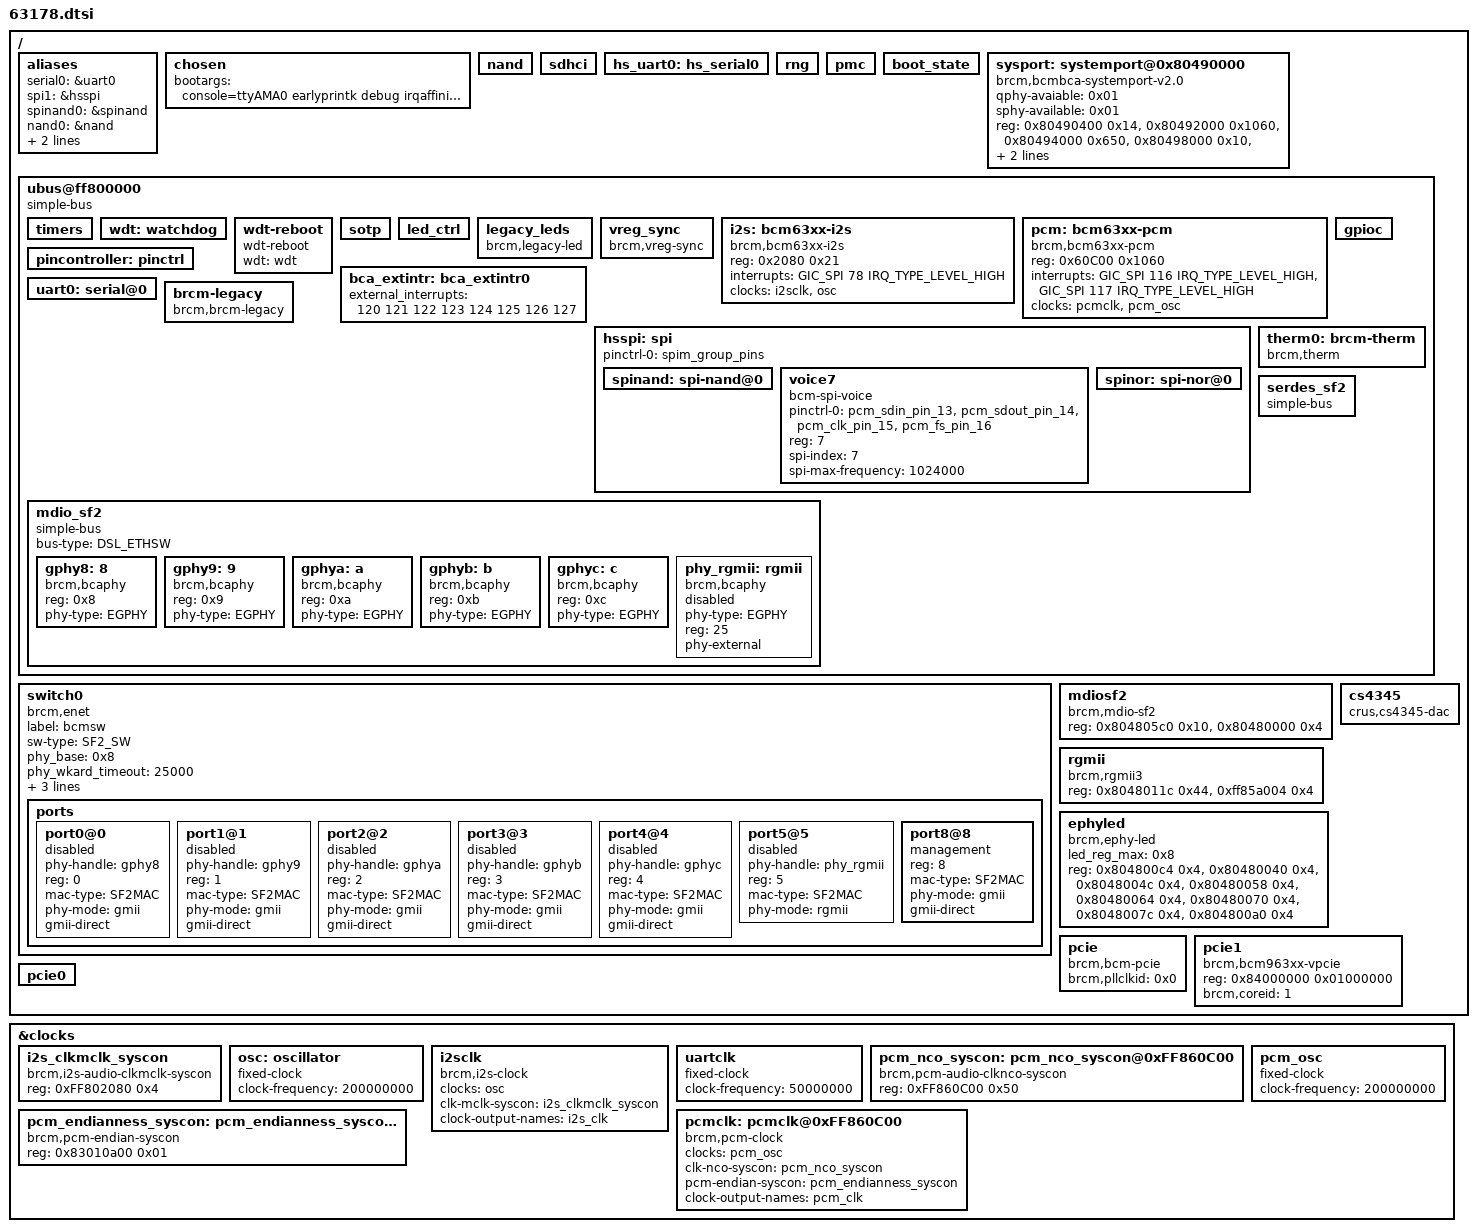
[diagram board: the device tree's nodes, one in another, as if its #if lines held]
/dts-v1/;

#define PMU_CORE0_SPI                   7
#define PMU_CORE1_SPI                   8
#define PMU_CORE2_SPI                   9


#include "linux_autoconf.h"

/* bootstrap reserved memory */
#include "../boot_rsvdmem.dtsi"

/ {
        /* arch */
	#define MODEL "Broadcom BCM963178"
	#define COMPATIBLE "brcm,bcm963178"
	#include "../ip/bcm_cortexA7_tri.dtsi"

	#define PERIPH_CLK		200000000
	#define HS_SPI_PLL_CLK	200000000
	#include "../ip/bcm_clocks.dtsi"

	/* broadcom memory reservations */
	#include "../bcm_rsvdmem.dtsi"

	aliases {
		serial0 = &uart0;
		spi1 = &hsspi; /* 0 = legacy, 1 = high speed */
		spinand0 = &spinand;
		nand0 = &nand;
		spinor0 = &spinor;
		hs_serial0  = &hs_uart0;
	};
	chosen {
		bootargs = "console=ttyAMA0 earlyprintk debug irqaffinity=0 pci=pcie_bus_safe isolcpus=2 rootwait";
        };

	/* memc */
	#define BP_DDR_SUPPORT_VTT                  1
	#define BP_DDR_SUPPORT_VTT_DIS_PASVTERM     0
	#define BP_DDR_63178_DEFAULT           BP_DDR_VTT_DIS_NOTERM
	#include "../ip/memc.dtsi"

	nand: nand {
		#define NAND_CTRL_OFFSET		0xff801800
		#define NAND_CTRL_SIZE			0x400
		#define NAND_INTR_OFFSET		0xff802000
		#define NAND_INTR_SIZE			0x10
		#define NAND_CACHE_OFFSET		0xff801C00
		#define NAND_CACHE_SIZE			0x200
		#include "../ip/bcm_nand7_1.dtsi"
	};
        /* EMMC */
	sdhci: sdhci {
		#define SDHCI_OFFSET			0xff810000
		#define SDHCI_SIZE			0x100
		#define SDHCI_TOPCFG_OFFSET		0xff810100
		#define SDHCI_TOPCFG_SIZE		0x100
		#define SDHCI_BOOT_OFFSET		0xff810200
		#define SDHCI_BOOT_SIZE			0x40
		#define SDHCI_AHBSS_CTRL_OFFSET		0xff810300
		#define SDHCI_AHBSS_CTRL_SIZE		0x100
		#define SDIO_EMMC_SPI			86
		#include "../ip/bcm_sdhci.dtsi"
	};
	hs_uart0: hs_serial0 {
		#define UART_OFFSET			0xff810400
		#define UART_SIZE			0x1E0
		#define UART_SPI			34
		#include "../ip/bcm_hs_uart.dtsi"
	};
	/* RNG */
	rng: rng {
		#define RNG200_OFFSET                   0xff800b80
		#define RNG200_SIZE                     0x30
		#include "../ip/bcm_rng200.dtsi"
	};

	/* PMC */
	pmc: pmc {
		#define PMC_REG_OFFSET              0x80301018 
		#define PMC_REG_SIZE                0x5080
		#define PROCMON_REG_OFFSET          0x80320000
		#define PROCMON_REG_SIZE            0x240
		#define MAESTRO_REG_OFFSET          0x80300400
		#define MAESTRO_REG_SIZE            0x5d0
		#define MAESTRO_DTCM_REG_OFFSET     0x80380000
		#define MAESTRO_DTCM_REG_SIZE       0x1000
		#include "../ip/bcm_pmc_3_2.dtsi"
	};

	/* boot state */
	boot_state: boot_state {
		#define RESET_REASON_OFFSET  0xff802628
		#define RESET_REASON_SIZE    0x4
		#define RESET_STATUS_OFFSET  0xff85a03c
		#define RESET_STATUS_SIZE    0x4
		#include "../ip/bcm_boot_state_v2.dtsi"
	};


	sysport: systemport@0x80490000 {
		compatible = "brcm,bcmbca-systemport-v2.0";
		qphy-avaiable=<0x01>;
		sphy-available=<0x01>;
		reg-names = "systemport-rbuf-base", "systemport-rdma-base",
				"systemport-tdma-base",
				"systemport-gib-base",
				"systemport-umac-base",
				"systemport-topctrl-base";
		reg =		<0x80490400 0x14>,
				<0x80492000 0x1060>,
				<0x80494000 0x650>,
				<0x80498000 0x10>,
				<0x00000000 0x00>,  
				<0x80490000 0x10>;
		ethsw = <&switch0>;
	};


	ubus@ff800000 {
		compatible = "simple-bus";
		#address-cells = <1>;
		#size-cells = <1>;
		ranges = <0 0xff800000 0x7fffff>;

		/* periph timers */
		timers: timers {
			#define TIMERS_OFFSET		0x400
			#define TIMERS__SIZE		0x48
			#define TIMER0_SPI			11
			#define TIMER1_SPI			12
			#define TIMER2_SPI			13
			#define TIMER3_SPI			14
			#include "../ip/bcm_timer.dtsi"
		};

		/* watchdog */
		wdt: watchdog {
			#define WATCHDOG_OFFSET			0x480
			#define WATCHDOG_SIZE			0x10
			#define WATCHDOG_TIMEOUT		80
			#include "../ip/bcm_wdt.dtsi"
		};
		/* watchdog reboot */
		wdt-reboot {
			compatible = "wdt-reboot";
			wdt = <&wdt>;
		};

		/* sotp */
		sotp {
			#define SOTP_OFFSET			0xc00
			#define SOTP_SIZE			0x84
			#include "../ip/bcm_sotp.dtsi"
		};
		
		/* Led Controller */
		led_ctrl: led_ctrl {
			#define CLED_GLBL_CTRL_OFFSET           0x3000
			#define CLED_GLBL_CTRL_SIZE             0x4
			#define CLED_HW_EN_OFFSET               0x3004
			#define CLED_HW_EN_SIZE                 0x4
			#define CLED_SER_SHIFT_OFFSET           0x3008
			#define CLED_SER_SHIFT_SIZE             0x4
			#define CLED_HW_POLARITY_OFFSET         0x300c
			#define CLED_HW_POLARITY_SIZE           0x4
			#define CLED_SW_SET_OFFSET              0x3010
			#define CLED_SW_SET_SIZE                0x4
			#define CLED_SW_POLARITY_OFFSET         0x3014
			#define CLED_SW_POLARITY_SIZE           0x4
			#define CLED_CH_ACTIVATE_OFFSET         0x301c
			#define CLED_CH_ACTIVATE_SIZE           0x4
			#define CLED_XX_CONFIG_OFFSET           0x3020
			#define CLED_XX_CONFIG_SIZE             0x200
			#define CLED_SERIAL_POLARITY_OFFSET     0x3454
			#define CLED_SERIAL_POLARITY_SIZE       0x4
			#define CLED_PARALLEL_POLARITY_OFFSET   0x3018
			#define CLED_PARALLEL_POLARITY_SIZE     0x4
			#define MAX_SUPPORTED_LEDS              32

			status = "okay";
			#include "../ip/bcm_cled_legacy_ctrl.dtsi"
			#include "63178_leds.dtsi"
		};

		legacy_leds: legacy_leds {
			compatible = "brcm,legacy-led";
		};

		vreg_sync: vreg_sync {
			compatible = "brcm,vreg-sync";
		};

		i2s: bcm63xx-i2s {
			compatible = "brcm,bcm63xx-i2s";
			reg = <0x2080 0x21>;
			interrupts = <GIC_SPI 78 IRQ_TYPE_LEVEL_HIGH>;
			clocks = <&i2sclk>, <&osc>;
			clock-names = "i2sclk","i2sosc"; 
		};
		pcm: bcm63xx-pcm {
			compatible = "brcm,bcm63xx-pcm";
			reg = <0x60C00 0x1060>;
			interrupts = <GIC_SPI 116 IRQ_TYPE_LEVEL_HIGH>,<GIC_SPI 117 IRQ_TYPE_LEVEL_HIGH>;
			clocks = <&pcmclk>, <&pcm_osc>;
			clock-names = "pcmclk","pcmosc"; 
		};
		/* pinctrl */
		pincontroller: pinctrl {
			#define PINCTRL_OFFSET       0x554
			#define PINCTRL_SIZE         0xc
			#define PINCTRL_NUM_PINS     88
			#define PINCTRL_NUM_FUNC     8
			#define PINCTRL_GPIO_FUNC    5
			#include "../ip/bcm_bca_pinctrl.dtsi"
			#include "63178_pinctrl.dtsi"
		};
		/* gpio */
		gpioc: gpioc {
			#define GPIO_DIR_OFFSET      0x500
			#define GPIO_DIR_SIZE        0x20
			#define GPIO_DATA_OFFSET     0x520
			#define GPIO_DATA_SIZE       0x20
			#define NUM_OF_GPIOS         88
			#include "../ip/bcm_bca_gpio.dtsi"
		};

		/* external interrups */
		bca_extintr: bca_extintr0 {
			#define EXTINTR_OFFSET       0x4
			#define EXTINTR_SIZE         0x48
			#define MAX_EXT_INTR         8
			#include "../ip/bcm_bca_extintr.dtsi"
			external_interrupts = <120 121 122 123 124 125 126 127>;
		};
		
		/* UART 1*/
		uart0: serial@0 {
			#define UART_OFFSET			0x12000
			#define UART_SIZE			0x1000
			#define UART_SPI			32
			#define UART_CLK_LABEL			refclk50mhz
			#define UART_CLK			50000000
			#include "../ip/bcm_arm_uart.dtsi"
		};
		/* HS SPI */
		hsspi: spi {
			pinctrl-0 = <&spim_group_pins>;
			pinctrl-names = "default";
			#define HS_SPI_OFFSET			0x1000
			#define HS_SPI_SIZE			0x600
			#define HS_SPI_MAX_FREQ			100000000
			#define HS_SPIM_SPI			37
			#include "../ip/bcm_hsspi.dtsi"
			spinand: spi-nand@0 {
				#define SPINAND_MAX_FREQ	100000000
				#include "../ip/bcm_spinand.dtsi"
			};
			voice7 {
				pinctrl-0 = <&pcm_sdin_pin_13 &pcm_sdout_pin_14 &pcm_clk_pin_15 &pcm_fs_pin_16>;
				pinctrl-names = "default";
				compatible = "bcm-spi-voice";
				reg = <7>; /* chip select 7 */
				spi-index = <7>;/* ZSI/ISI header position index */
				spi-max-frequency = <1024000>;
			};	
			spinor: spi-nor@0 {
				#define SPINOR_MAX_FREQ	50000000
				#include "../ip/bcm_spinor.dtsi"
			};
		};
		brcm-legacy {
			compatible = "brcm,brcm-legacy";
		};
		


		therm0: brcm-therm {
			compatible = "brcm,therm";
			status = "okay";
		};

		mdio_sf2: mdio_sf2 {
			compatible = "simple-bus";
			bus-type = "DSL_ETHSW";

			gphy8:8 {
				compatible = "brcm,bcaphy";
				reg = <0x8>;
				phy-type = "EGPHY";
			};
			gphy9:9 {
				compatible = "brcm,bcaphy";
				reg = <0x9>;
				phy-type = "EGPHY";
			};
			gphya:a {
				compatible = "brcm,bcaphy";
				reg = <0xa>;
				phy-type = "EGPHY";
			};
			gphyb:b {
				compatible = "brcm,bcaphy";
				reg = <0xb>;
				phy-type = "EGPHY";
			};
			gphyc:c {
				compatible = "brcm,bcaphy";
				reg = <0xc>;
				phy-type = "EGPHY";
			};
			phy_rgmii:rgmii {
				compatible = "brcm,bcaphy";
				phy-type = "EGPHY";
				reg = <25>;
				status = "disabled";
				phy-external;
			};
		};

		serdes_sf2: serdes_sf2 {
			compatible = "simple-bus";
		};
	};

	switch0:switch0 {
		compatible = "brcm,enet", "brcm,bcmbca-sf2";
		label = "bcmsw";
		sw-type = "SF2_SW";

		phy_base = <0x8>;
		phy_wkard_timeout = <25000>;
		reg-names = "switchcore-base",
					"switchreg-base",
					"switchmdio-base",
					"qphy-ctrl",
					"sphy-ctrl",
					"phy-test-ctrl";

		reg = <0x80400000 0x72724>,
			<0x80480000 0x458>,
			<0x804805c0 0x10>,
			<0x8048001c 0x04>,
			<0x80480024 0x04>,
			<0x80480018 0x04>;

		ports {
			port0@0 {
				phy-handle = <&gphy8>;
				reg = <0>;
				mac-type = "SF2MAC";
				phy-mode = "gmii";
				gmii-direct;
				status = "disabled";
			};
			port1@1 {
				phy-handle = <&gphy9>;
				reg = <1>;
				mac-type = "SF2MAC";
				phy-mode = "gmii";
				gmii-direct;
				status = "disabled";
			};
			port2@2 {
				phy-handle = <&gphya>;
				reg = <2>;
				mac-type = "SF2MAC";
				phy-mode = "gmii";
				gmii-direct;
				status = "disabled";
			};
			port3@3 {
				phy-handle = <&gphyb>;
				reg = <3>;
				mac-type = "SF2MAC";
				phy-mode = "gmii";
				gmii-direct;
				status = "disabled";
			};
			port4@4 {
				phy-handle = <&gphyc>;
				reg = <4>;
				mac-type = "SF2MAC";
				phy-mode = "gmii";
				gmii-direct;
				status = "disabled";
			};
			port5@5 {
				phy-handle = <&phy_rgmii>;
				reg = <5>;
				mac-type = "SF2MAC";
				phy-mode = "rgmii";
				status = "disabled";
			};
			port8@8 {
				management;
				reg = <8>;
				mac-type = "SF2MAC";
				phy-mode = "gmii";
				gmii-direct;
				status = "okay";
			};
		};
	};

	mdiosf2 {
		compatible = "brcm,mdio-sf2";
		reg = <0x804805c0 0x10>,
		      <0x80480000 0x4>;
	};

	rgmii: rgmii {
		compatible = "brcm,rgmii3";
		reg = <0x8048011c  0x44>,
		      <0xff85a004  0x4>;
	};

	ephyled {
	    compatible = "brcm,ephy-led";
            led_reg_max=<0x8>;
            reg-names = "aggregate_ctrl", "led_reg_0", "led_reg_1", "led_reg_2", "led_reg_3", "led_reg_4", "led_reg_5", "led_reg_8"; 
            reg = <0x804800c4 0x4>, < 0x80480040 0x4>, < 0x8048004c 0x4>, < 0x80480058 0x4>, < 0x80480064 0x4>, < 0x80480070 0x4>, < 0x8048007c 0x4>, < 0x804800a0 0x4>;
	};


	cs4345 {
		compatible = "crus,cs4345-dac";
	};

#if defined(CONFIG_BCM_PCIE_HCD) || defined(CONFIG_BCM_PCIE_HCD_MODULE)
	/* pcie common */
	pcie: pcie {
		compatible = "brcm,bcm-pcie";
		device_type = "cpci";
		brcm,pllclkid = <0x0>;
	};

	/* pcie core 1 (internal wifi first) */
	pcie1: pcie1 {
		compatible = "brcm,bcm963xx-vpcie";
		device_type = "vpci";
		reg = <0x84000000 0x01000000>;

		brcm,coreid = <1>;
	};

	/* pcie core 0 */
	pcie0: pcie0 {
		#define PCIE_ID				0
		#define PCIE_SPI			43
		#define PCIE_ADDR			0x80040000
		#define PCIE_SIZE			0x0000A000
					      /*           flags    pci_addr     cpu_addr     size */
		#define PCIE_RANGE			0x02000000 0 0xC0000000 0xC0000000 0 0x10000000
		#include "../ip/bcm_pcie_core.dtsi"
	};
#endif

};

&clocks {
	#address-cells = <1>;
	#size-cells    = <1>;
	ranges;

	i2s_clkmclk_syscon: i2s_clkmclk_syscon{
		compatible        = "brcm,i2s-audio-clkmclk-syscon", "syscon";
		reg               = <0xFF802080 0x4>;
	};
	osc: oscillator {
		#clock-cells      = <0>;
		compatible        = "fixed-clock";
		clock-frequency   = <200000000>; /* xpon 200MHz output */
	};

	i2sclk: i2sclk {
		#clock-cells       = <0>;
		compatible         = "brcm,i2s-clock";
		clocks = <&osc>;
		clk-mclk-syscon    = <&i2s_clkmclk_syscon>;
		clock-output-names = "i2s_clk";
	};

	uartclk: uartclk {
		compatible = "fixed-clock";
		#clock-cells = <0>;
		clock-frequency = <50000000>;
	};
	
	pcm_nco_syscon: pcm_nco_syscon@0xFF860C00 {
		compatible = "brcm,pcm-audio-clknco-syscon", "syscon";
		reg = <0xFF860C00 0x50>; /* temp setting here. to do: size should be re-cal for only we need.*/
	};
	pcm_osc: pcm_osc {
		#clock-cells = <0>;
		compatible = "fixed-clock";
		clock-frequency = <200000000>; /* 200.00MHz fixed output */
	};

	pcm_endianness_syscon: pcm_endianness_syscon@0x83010a00 {
		compatible = "brcm,pcm-endian-syscon", "syscon";
		reg = <0x83010a00 0x01>;
	};

	pcmclk: pcmclk@0xFF860C00 {
		#clock-cells = <0>;
		compatible = "brcm,pcm-clock";
		clocks = <&pcm_osc>;
		clk-nco-syscon = <&pcm_nco_syscon>;
		pcm-endian-syscon = <&pcm_endianness_syscon>;
		clock-output-names = "pcm_clk";

	};
};

&nand {
	status = "okay";
};
&uart0 {
	status = "okay";
};
&wdt {
	status = "okay";
};
&hsspi {
	status = "okay";
};
&spinand {
	status = "okay";
};
&spinor {
	status = "okay";
};
&rgmii {
	status = "okay";
};
#if defined(CONFIG_BCM_PCIE_HCD) || defined(CONFIG_BCM_PCIE_HCD_MODULE)
&pcie0 {
	status = "okay";
};
#endif
